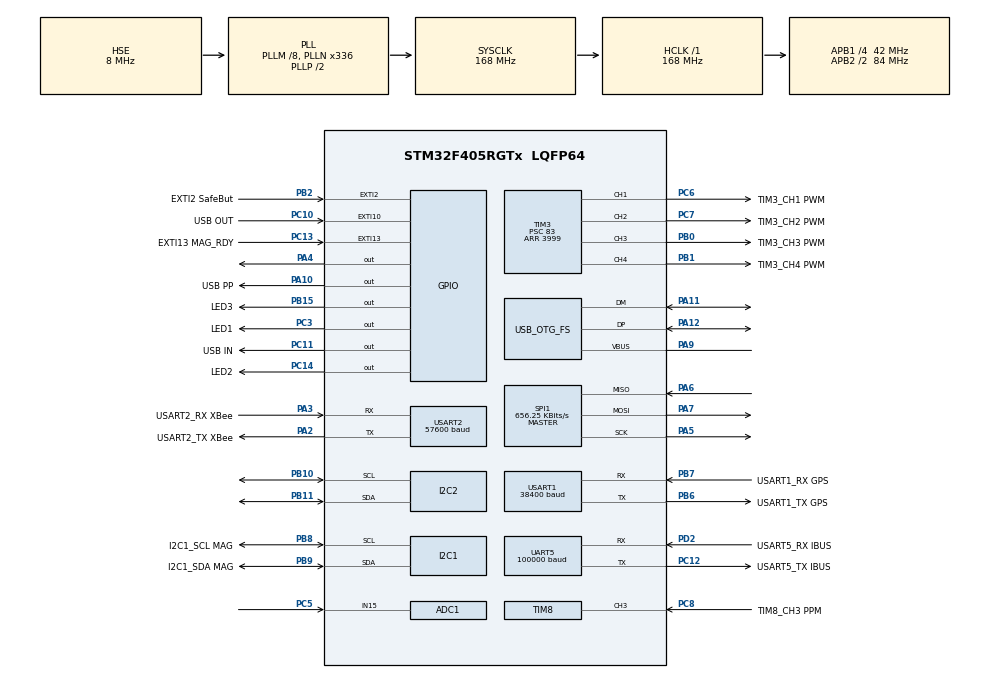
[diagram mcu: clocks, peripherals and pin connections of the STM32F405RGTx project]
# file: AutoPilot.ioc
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ADC1.Channel-16\#ChannelRegularConversion=ADC_CHANNEL_15
ADC1.ClockPrescaler=ADC_CLOCK_SYNC_PCLK_DIV4
ADC1.ContinuousConvMode=DISABLE
ADC1.DMAContinuousRequests=DISABLE
ADC1.DataAlign=ADC_DATAALIGN_RIGHT
ADC1.DiscontinuousConvMode=DISABLE
ADC1.EOCSelection=ADC_EOC_SINGLE_CONV
ADC1.EnableAnalogWatchDog=false
ADC1.ExternalTrigConvEdge=ADC_EXTERNALTRIGCONVEDGE_NONE
ADC1.InjNumberOfConversion=0
ADC1.NbrOfConversion=1
ADC1.NbrOfConversionFlag=1
ADC1.Rank-16\#ChannelRegularConversion=1
ADC1.Resolution=ADC_RESOLUTION_12B
ADC1.SamplingTime-16\#ChannelRegularConversion=ADC_SAMPLETIME_3CYCLES
ADC1.ScanConvMode=DISABLE
ADC1.master=1
Dma.I2C1_RX.5.Direction=DMA_PERIPH_TO_MEMORY
Dma.I2C1_RX.5.FIFOMode=DMA_FIFOMODE_DISABLE
Dma.I2C1_RX.5.Instance=DMA1_Stream0
Dma.I2C1_RX.5.MemDataAlignment=DMA_MDATAALIGN_BYTE
Dma.I2C1_RX.5.MemInc=DMA_MINC_ENABLE
Dma.I2C1_RX.5.Mode=DMA_NORMAL
Dma.I2C1_RX.5.PeriphDataAlignment=DMA_PDATAALIGN_BYTE
Dma.I2C1_RX.5.PeriphInc=DMA_PINC_DISABLE
Dma.I2C1_RX.5.Priority=DMA_PRIORITY_LOW
Dma.I2C2_RX.6.Direction=DMA_PERIPH_TO_MEMORY
Dma.I2C2_RX.6.FIFOMode=DMA_FIFOMODE_DISABLE
Dma.I2C2_RX.6.Instance=DMA1_Stream2
Dma.I2C2_RX.6.MemDataAlignment=DMA_MDATAALIGN_BYTE
Dma.I2C2_RX.6.MemInc=DMA_MINC_ENABLE
Dma.I2C2_RX.6.Mode=DMA_NORMAL
Dma.I2C2_RX.6.PeriphDataAlignment=DMA_PDATAALIGN_BYTE
Dma.I2C2_RX.6.PeriphInc=DMA_PINC_DISABLE
Dma.I2C2_RX.6.Priority=DMA_PRIORITY_LOW
Dma.I2C2_TX.7.Direction=DMA_MEMORY_TO_PERIPH
Dma.I2C2_TX.7.FIFOMode=DMA_FIFOMODE_DISABLE
Dma.I2C2_TX.7.Instance=DMA1_Stream7
Dma.I2C2_TX.7.MemDataAlignment=DMA_MDATAALIGN_BYTE
Dma.I2C2_TX.7.MemInc=DMA_MINC_ENABLE
Dma.I2C2_TX.7.Mode=DMA_NORMAL
Dma.I2C2_TX.7.PeriphDataAlignment=DMA_PDATAALIGN_BYTE
Dma.I2C2_TX.7.PeriphInc=DMA_PINC_DISABLE
Dma.I2C2_TX.7.Priority=DMA_PRIORITY_LOW
Dma.Request0=USART2_TX
Dma.Request1=USART2_RX
Dma.Request2=USART1_RX
Dma.Request3=SPI1_RX
Dma.Request4=SPI1_TX
Dma.Request5=I2C1_RX
Dma.Request6=I2C2_RX
Dma.Request7=I2C2_TX
Dma.SPI1_RX.3.Direction=DMA_PERIPH_TO_MEMORY
Dma.SPI1_RX.3.FIFOMode=DMA_FIFOMODE_DISABLE
Dma.SPI1_RX.3.Instance=DMA2_Stream2
Dma.SPI1_RX.3.MemDataAlignment=DMA_MDATAALIGN_BYTE
Dma.SPI1_RX.3.MemInc=DMA_MINC_ENABLE
Dma.SPI1_RX.3.Mode=DMA_NORMAL
Dma.SPI1_RX.3.PeriphDataAlignment=DMA_PDATAALIGN_BYTE
Dma.SPI1_RX.3.PeriphInc=DMA_PINC_DISABLE
Dma.SPI1_RX.3.Priority=DMA_PRIORITY_HIGH
Dma.SPI1_TX.4.Direction=DMA_MEMORY_TO_PERIPH
Dma.SPI1_TX.4.FIFOMode=DMA_FIFOMODE_DISABLE
Dma.SPI1_TX.4.Instance=DMA2_Stream3
Dma.SPI1_TX.4.MemDataAlignment=DMA_MDATAALIGN_BYTE
Dma.SPI1_TX.4.MemInc=DMA_MINC_ENABLE
Dma.SPI1_TX.4.Mode=DMA_NORMAL
Dma.SPI1_TX.4.PeriphDataAlignment=DMA_PDATAALIGN_BYTE
Dma.SPI1_TX.4.PeriphInc=DMA_PINC_DISABLE
Dma.SPI1_TX.4.Priority=DMA_PRIORITY_HIGH
Dma.USART1_RX.2.Direction=DMA_PERIPH_TO_MEMORY
Dma.USART1_RX.2.FIFOMode=DMA_FIFOMODE_DISABLE
Dma.USART1_RX.2.Instance=DMA2_Stream5
Dma.USART1_RX.2.MemDataAlignment=DMA_MDATAALIGN_BYTE
Dma.USART1_RX.2.MemInc=DMA_MINC_ENABLE
Dma.USART1_RX.2.Mode=DMA_NORMAL
Dma.USART1_RX.2.PeriphDataAlignment=DMA_PDATAALIGN_BYTE
Dma.USART1_RX.2.PeriphInc=DMA_PINC_DISABLE
Dma.USART1_RX.2.Priority=DMA_PRIORITY_LOW
Dma.USART2_RX.1.Direction=DMA_PERIPH_TO_MEMORY
Dma.USART2_RX.1.FIFOMode=DMA_FIFOMODE_DISABLE
Dma.USART2_RX.1.Instance=DMA1_Stream5
Dma.USART2_RX.1.MemDataAlignment=DMA_MDATAALIGN_BYTE
Dma.USART2_RX.1.MemInc=DMA_MINC_ENABLE
Dma.USART2_RX.1.Mode=DMA_NORMAL
Dma.USART2_RX.1.PeriphDataAlignment=DMA_PDATAALIGN_BYTE
Dma.USART2_RX.1.PeriphInc=DMA_PINC_DISABLE
Dma.USART2_RX.1.Priority=DMA_PRIORITY_LOW
Dma.USART2_TX.0.Direction=DMA_MEMORY_TO_PERIPH
Dma.USART2_TX.0.FIFOMode=DMA_FIFOMODE_DISABLE
Dma.USART2_TX.0.Instance=DMA1_Stream6
Dma.USART2_TX.0.MemDataAlignment=DMA_MDATAALIGN_BYTE
Dma.USART2_TX.0.MemInc=DMA_MINC_ENABLE
Dma.USART2_TX.0.Mode=DMA_NORMAL
Dma.USART2_TX.0.PeriphDataAlignment=DMA_PDATAALIGN_BYTE
Dma.USART2_TX.0.PeriphInc=DMA_PINC_DISABLE
Dma.USART2_TX.0.Priority=DMA_PRIORITY_LOW
FREERTOS.INCLUDE_vTaskDelayUntil=1
FREERTOS.Tasks01=defaultTask,0,128,StartDefaultTask,Default
I2C1.I2C_Mode=I2C_Fast
I2C2.I2C_Mode=I2C_Fast
I2C2.OwnAddress=0x50
Mcu.Family=STM32F4
Mcu.Name=STM32F405RGTx
Mcu.Package=LQFP64
NVIC.DMA1_Stream0_IRQn=true\:0\:0\:false\:false\:true\:false
NVIC.DMA1_Stream2_IRQn=true\:5\:0\:false\:false\:true\:true
NVIC.DMA1_Stream5_IRQn=true\:0\:0\:false\:false\:true\:false
NVIC.DMA1_Stream6_IRQn=true\:5\:0\:false\:false\:true\:true
NVIC.DMA1_Stream7_IRQn=true\:5\:0\:false\:false\:true\:true
NVIC.DMA2_Stream2_IRQn=true\:5\:0\:false\:false\:true\:true
NVIC.DMA2_Stream3_IRQn=true\:5\:0\:false\:false\:true\:true
NVIC.DMA2_Stream5_IRQn=true\:5\:0\:false\:false\:true\:true
NVIC.EXTI15_10_IRQn=true\:15\:0\:true\:false\:true\:true
NVIC.EXTI2_IRQn=true\:9\:0\:true\:false\:true\:true
NVIC.FLASH_IRQn=true\:7\:0\:true\:false\:true\:true
NVIC.I2C1_EV_IRQn=true\:5\:0\:true\:false\:true\:true
NVIC.I2C2_EV_IRQn=true\:5\:0\:false\:false\:true\:true
NVIC.OTG_FS_IRQn=true\:5\:0\:false\:false\:true\:true
NVIC.PriorityGroup=NVIC_PRIORITYGROUP_4
NVIC.SPI1_IRQn=true\:6\:0\:true\:false\:true\:true
NVIC.TIM1_UP_TIM10_IRQn=true\:0\:0\:false\:false\:true\:false
NVIC.TIM4_IRQn=true\:0\:0\:false\:false\:true\:false
NVIC.TIM8_CC_IRQn=true\:13\:0\:true\:false\:true\:true
NVIC.TimeBase=TIM1_UP_TIM10_IRQn
NVIC.TimeBaseIP=TIM1
NVIC.UART5_IRQn=true\:12\:0\:true\:false\:true\:true
NVIC.USART1_IRQn=true\:11\:0\:true\:false\:true\:true
NVIC.USART2_IRQn=true\:10\:0\:true\:false\:true\:true
PA10.GPIO_Label=USB PP
PA10.Signal=GPIO_Output
PA11.Mode=Device_Only
PA11.Signal=USB_OTG_FS_DM
PA12.Mode=Device_Only
PA12.Signal=USB_OTG_FS_DP
PA13.Mode=JTAG_5_pins
PA13.Signal=SYS_JTMS-SWDIO
PA14.Mode=JTAG_5_pins
PA14.Signal=SYS_JTCK-SWCLK
PA15.Mode=JTAG_5_pins
PA15.Signal=SYS_JTDI
PA2.GPIO_Label=USART2_TX XBee
PA2.Mode=Asynchronous
PA2.Signal=USART2_TX
PA3.GPIO_Label=USART2_RX XBee
PA3.Mode=Asynchronous
PA3.Signal=USART2_RX
PA4.GPIO_Speed=GPIO_SPEED_FREQ_VERY_HIGH
PA4.PinState=GPIO_PIN_SET
PA4.Signal=GPIO_Output
PA5.Mode=Full_Duplex_Master
PA5.Signal=SPI1_SCK
PA6.Mode=Full_Duplex_Master
PA6.Signal=SPI1_MISO
PA7.Mode=Full_Duplex_Master
PA7.Signal=SPI1_MOSI
PA9.Mode=Activate_VBUS
PA9.Signal=USB_OTG_FS_VBUS
PB0.GPIO_Label=TIM3_CH3 PWM
PB0.Signal=S_TIM3_CH3
PB1.GPIO_Label=TIM3_CH4 PWM
PB1.Signal=S_TIM3_CH4
PB10.Mode=I2C
PB10.Signal=I2C2_SCL
PB11.Mode=I2C
PB11.Signal=I2C2_SDA
PB15.GPIO_Label=LED3
PB15.Signal=GPIO_Output
PB2.GPIO_Label=EXTI2 SafeBut
PB2.GPIO_ModeDefaultEXTI=GPIO_MODE_IT_RISING_FALLING
PB2.Signal=GPXTI2
PB3.Mode=JTAG_5_pins
PB3.Signal=SYS_JTDO-SWO
PB4.Mode=JTAG_5_pins
PB4.Signal=SYS_JTRST
PB6.GPIO_Label=USART1_TX GPS
PB6.Mode=Asynchronous
PB6.Signal=USART1_TX
PB7.GPIO_Label=USART1_RX GPS
PB7.Mode=Asynchronous
PB7.Signal=USART1_RX
PB8.GPIO_Label=I2C1_SCL MAG
PB8.Mode=I2C
PB8.Signal=I2C1_SCL
PB9.GPIO_Label=I2C1_SDA MAG
PB9.Mode=I2C
PB9.Signal=I2C1_SDA
PC10.GPIO_Label=USB OUT
PC10.GPIO_ModeDefaultEXTI=GPIO_MODE_IT_RISING_FALLING
PC10.Signal=GPXTI10
PC11.GPIO_Label=USB IN
PC11.Signal=GPIO_Output
PC12.GPIO_Label=USART5_TX IBUS
PC12.Mode=Asynchronous
PC12.Signal=UART5_TX
PC13-ANTI_TAMP.GPIO_Label=EXTI13 MAG_RDY
PC13-ANTI_TAMP.Signal=GPXTI13
PC14-OSC32_IN.GPIO_Label=LED2
PC14-OSC32_IN.Signal=GPIO_Output
PC3.GPIO_Label=LED1
PC3.Signal=GPIO_Output
PC5.Signal=ADCx_IN15
PC6.GPIO_Label=TIM3_CH1 PWM
PC6.Signal=S_TIM3_CH1
PC7.GPIO_Label=TIM3_CH2 PWM
PC7.Signal=S_TIM3_CH2
PC8.GPIO_Label=TIM8_CH3 PPM
PC8.Signal=S_TIM8_CH3
PD2.GPIO_Label=USART5_RX IBUS
PD2.Mode=Asynchronous
PD2.Signal=UART5_RX
PH0-OSC_IN.Mode=HSE-External-Oscillator
PH0-OSC_IN.Signal=RCC_OSC_IN
PH1-OSC_OUT.Mode=HSE-External-Oscillator
PH1-OSC_OUT.Signal=RCC_OSC_OUT
ProjectManager.HeapSize=0x200
ProjectManager.StackSize=0x400
ProjectManager.TargetToolchain=MDK-ARM V5
RCC.48MHZClocksFreq_Value=48000000
RCC.AHBFreq_Value=168000000
RCC.APB1CLKDivider=RCC_HCLK_DIV4
RCC.APB1Freq_Value=42000000
RCC.APB1TimFreq_Value=84000000
RCC.APB2CLKDivider=RCC_HCLK_DIV2
RCC.APB2Freq_Value=84000000
RCC.APB2TimFreq_Value=168000000
RCC.CortexFreq_Value=168000000
RCC.HCLKFreq_Value=168000000
RCC.HSE_VALUE=8000000
RCC.HSI_VALUE=16000000
RCC.LSE_VALUE=32768
RCC.PLLM=8
RCC.PLLN=336
RCC.PLLQ=7
RCC.SYSCLKFreq_VALUE=168000000
RCC.SYSCLKSource=RCC_SYSCLKSOURCE_PLLCLK
RCC.VCOOutputFreq_Value=336000000
SH.ADCx_IN15.0=ADC1_IN15,IN15
SH.S_TIM3_CH1.0=TIM3_CH1,PWM Generation1 CH1
SH.S_TIM3_CH2.0=TIM3_CH2,PWM Generation2 CH2
SH.S_TIM3_CH3.0=TIM3_CH3,PWM Generation3 CH3
SH.S_TIM3_CH4.0=TIM3_CH4,PWM Generation4 CH4
SH.S_TIM8_CH3.0=TIM8_CH3,Input_Capture3_from_TI3
SPI1.BaudRatePrescaler=SPI_BAUDRATEPRESCALER_128
SPI1.CLKPhase=SPI_PHASE_1EDGE
SPI1.CLKPolarity=SPI_POLARITY_LOW
SPI1.CalculateBaudRate=656.25 KBits/s
SPI1.Direction=SPI_DIRECTION_2LINES
SPI1.FirstBit=SPI_FIRSTBIT_MSB
SPI1.Mode=SPI_MODE_MASTER
SPI1.VirtualType=VM_MASTER
TIM3.Channel-PWM\ Generation1\ CH1=TIM_CHANNEL_1
TIM3.Channel-PWM\ Generation2\ CH2=TIM_CHANNEL_2
TIM3.Channel-PWM\ Generation3\ CH3=TIM_CHANNEL_3
TIM3.Channel-PWM\ Generation4\ CH4=TIM_CHANNEL_4
TIM3.Period=3999
TIM3.Prescaler=83
TIM4.Period=7999
TIM4.Prescaler=20
TIM8.Channel-Input_Capture3_from_TI3=TIM_CHANNEL_3
TIM8.ICPolarity_CH3=TIM_INPUTCHANNELPOLARITY_BOTHEDGE
TIM8.Period=39999
TIM8.Prescaler=83
UART5.BaudRate=100000
UART5.Mode=UART_MODE_RX
UART5.Parity=UART_PARITY_EVEN
UART5.StopBits=UART_STOPBITS_2
UART5.VirtualMode=Asynchronous
UART5.WordLength=UART_WORDLENGTH_9B
USART1.BaudRate=38400
USART1.VirtualMode=VM_ASYNC
USART2.BaudRate=57600
USART2.VirtualMode=VM_ASYNC
USB_DEVICE.CLASS_NAME_FS=CDC
USB_DEVICE.USBD_HandleTypeDef-CDC_FS=hUsbDeviceFS
USB_DEVICE.VirtualMode-CDC_FS=Cdc
USB_DEVICE.VirtualModeFS=Cdc_FS
USB_OTG_FS.VirtualMode=Device_Only
VP_CRC_VS_CRC.Mode=CRC_Activate
VP_FREERTOS_VS_ENABLE.Mode=Enabled
VP_SYS_VS_tim1.Mode=TIM1
VP_TIM4_VS_ClockSourceINT.Mode=Internal
VP_TIM8_VS_ClockSourceINT.Mode=Internal
VP_USB_DEVICE_VS_USB_DEVICE_CDC_FS.Mode=CDC_FS
board=AutoPilot

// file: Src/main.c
/**
  ******************************************************************************
  * File Name          : main.c
  * Description        : Main program body
  ******************************************************************************
  *
  * COPYRIGHT(c) 2016 STMicroelectronics
  *
  * Redistribution and use in source and binary forms, with or without modification,
  * are permitted provided that the following conditions are met:
  *   1. Redistributions of source code must retain the above copyright notice,
  *      this list of conditions and the following disclaimer.
  *   2. Redistributions in binary form must reproduce the above copyright notice,
  *      this list of conditions and the following disclaimer in the documentation
  *      and/or other materials provided with the distribution.
  *   3. Neither the name of STMicroelectronics nor the names of its contributors
  *      may be used to endorse or promote products derived from this software
  *      without specific prior written permission.
  *
  * THIS SOFTWARE IS PROVIDED BY THE COPYRIGHT HOLDERS AND CONTRIBUTORS "AS IS"
  * AND ANY EXPRESS OR IMPLIED WARRANTIES, INCLUDING, BUT NOT LIMITED TO, THE
  * IMPLIED WARRANTIES OF MERCHANTABILITY AND FITNESS FOR A PARTICULAR PURPOSE ARE
  * DISCLAIMED. IN NO EVENT SHALL THE COPYRIGHT HOLDER OR CONTRIBUTORS BE LIABLE
  * FOR ANY DIRECT, INDIRECT, INCIDENTAL, SPECIAL, EXEMPLARY, OR CONSEQUENTIAL
  * DAMAGES (INCLUDING, BUT NOT LIMITED TO, PROCUREMENT OF SUBSTITUTE GOODS OR
  * SERVICES; LOSS OF USE, DATA, OR PROFITS; OR BUSINESS INTERRUPTION) HOWEVER
  * CAUSED AND ON ANY THEORY OF LIABILITY, WHETHER IN CONTRACT, STRICT LIABILITY,
  * OR TORT (INCLUDING NEGLIGENCE OR OTHERWISE) ARISING IN ANY WAY OUT OF THE USE
  * OF THIS SOFTWARE, EVEN IF ADVISED OF THE POSSIBILITY OF SUCH DAMAGE.
  *
  ******************************************************************************
  */
#include "stm32f4xx_hal.h"
#include "cmsis_os.h"
#include "usb_device.h"

/* USER CODE BEGIN Includes */
#include "../Modules/task_manager.h"

/*
#include "../Devices/data_link.h"
#include "../Devices/motor_pwm.h"
#include "../Devices/GPS.h"
#include "../Devices/battery.h"
#include "../Devices/led.h"
#include "../Devices/receiver.h"
#include "../Devices/mpu6000_spi.h"
#include "../Devices/rom.h"
#include "../Devices/hmc5883l_i2c.h"
#include "../Modules/sensors_task.h"
#include "../Modules/commander.h"
#include "../Modules/stabilizer.h"
*/

/* USER CODE END Includes */

ADC_HandleTypeDef hadc1;

CRC_HandleTypeDef hcrc;

I2C_HandleTypeDef hi2c1;
I2C_HandleTypeDef hi2c2;
DMA_HandleTypeDef hdma_i2c1_rx;
DMA_HandleTypeDef hdma_i2c2_rx;
DMA_HandleTypeDef hdma_i2c2_tx;

SPI_HandleTypeDef hspi1;
DMA_HandleTypeDef hdma_spi1_rx;
DMA_HandleTypeDef hdma_spi1_tx;

TIM_HandleTypeDef htim3;
TIM_HandleTypeDef htim4;
TIM_HandleTypeDef htim8;

UART_HandleTypeDef huart5;
UART_HandleTypeDef huart1;
UART_HandleTypeDef huart2;
DMA_HandleTypeDef hdma_usart1_rx;
DMA_HandleTypeDef hdma_usart2_tx;
DMA_HandleTypeDef hdma_usart2_rx;

osThreadId defaultTaskHandle;

/* USER CODE BEGIN PV */
/* Private variables ---------------------------------------------------------*/

/* USER CODE END PV */

void SystemClock_Config(void);
void Error_Handler(void);
static void MX_GPIO_Init(void);
static void MX_DMA_Init(void);
static void MX_ADC1_Init(void);
static void MX_CRC_Init(void);
static void MX_I2C1_Init(void);
static void MX_UART5_Init(void);
static void MX_TIM3_Init(void);
static void MX_USART1_UART_Init(void);
static void MX_I2C2_Init(void);
static void MX_TIM8_Init(void);
static void MX_SPI1_Init(void);
static void MX_USART2_UART_Init(void);
static void MX_TIM4_Init(void);
void StartDefaultTask(void const * argument);

void HAL_TIM_MspPostInit(TIM_HandleTypeDef *htim);

/* USER CODE BEGIN PFP */
/* Private function prototypes -----------------------------------------------*/

/* USER CODE END PFP */

int main(void)
{

  /* MCU Configuration----------------------------------------------------------*/

  /* Reset of all peripherals, Initializes the Flash interface and the Systick. */
  HAL_Init();

  /* Configure the system clock */
  SystemClock_Config();

  /* Initialize all configured peripherals */
  MX_GPIO_Init();
  MX_DMA_Init();
  MX_ADC1_Init();
  MX_CRC_Init();
  MX_I2C1_Init();
  MX_UART5_Init();
  MX_TIM3_Init();
  MX_USART1_UART_Init();
  MX_I2C2_Init();
  MX_TIM8_Init();
  MX_SPI1_Init();
  MX_USART2_UART_Init();
  MX_TIM4_Init();

  /* Create the thread(s) */
  /* definition and creation of defaultTask */
  osThreadDef(defaultTask, StartDefaultTask, osPriorityNormal, 0, 128);
  defaultTaskHandle = osThreadCreate(osThread(defaultTask), NULL);

  /* USER CODE BEGIN RTOS_THREADS */
  /* add threads, ... */
//	xTaskCreate( vLED1Task, "LED0", configMINIMAL_STACK_SIZE, NULL, tskIDLE_PRIORITY+3, NULL );
//  xTaskCreate( vLED2Task, "LED1", configMINIMAL_STACK_SIZE, NULL, tskIDLE_PRIORITY+3, NULL );
//  GPSInit();
/*	led_init();
	motor_init();
	data_link_init();
	receiver_init();
//	data_send_start();
	eeprom_init();
	battery_init();
	mpu6000_cfg();
	hmc5883l_cfg();
	mpu_fast_init();
	hmc_fast_init();
	sensorsTaskInit();
	commanderInit();*/
//	stabilizerInit();
	taskManagerInit();

	vTaskStartScheduler();
//	start_manager();
  /* USER CODE END RTOS_THREADS */

  /* Start scheduler */
  osKernelStart();

  /* We should never get here as control is now taken by the scheduler */

  /* Infinite loop */
  while (1)
  {

  }

}

/** System Clock Configuration
*/
void SystemClock_Config(void)
{

  RCC_OscInitTypeDef RCC_OscInitStruct;
  RCC_ClkInitTypeDef RCC_ClkInitStruct;

  __HAL_RCC_PWR_CLK_ENABLE();

  __HAL_PWR_VOLTAGESCALING_CONFIG(PWR_REGULATOR_VOLTAGE_SCALE1);

  RCC_OscInitStruct.OscillatorType = RCC_OSCILLATORTYPE_HSE;
  RCC_OscInitStruct.HSEState = RCC_HSE_ON;
  RCC_OscInitStruct.PLL.PLLState = RCC_PLL_ON;
  RCC_OscInitStruct.PLL.PLLSource = RCC_PLLSOURCE_HSE;
  RCC_OscInitStruct.PLL.PLLM = 8;
  RCC_OscInitStruct.PLL.PLLN = 336;
  RCC_OscInitStruct.PLL.PLLP = RCC_PLLP_DIV2;
  RCC_OscInitStruct.PLL.PLLQ = 7;
  if (HAL_RCC_OscConfig(&RCC_OscInitStruct) != HAL_OK)
  {
    Error_Handler();
  }

  RCC_ClkInitStruct.ClockType = RCC_CLOCKTYPE_HCLK|RCC_CLOCKTYPE_SYSCLK
                              |RCC_CLOCKTYPE_PCLK1|RCC_CLOCKTYPE_PCLK2;
  RCC_ClkInitStruct.SYSCLKSource = RCC_SYSCLKSOURCE_PLLCLK;
  RCC_ClkInitStruct.AHBCLKDivider = RCC_SYSCLK_DIV1;
  RCC_ClkInitStruct.APB1CLKDivider = RCC_HCLK_DIV4;
  RCC_ClkInitStruct.APB2CLKDivider = RCC_HCLK_DIV2;
  if (HAL_RCC_ClockConfig(&RCC_ClkInitStruct, FLASH_LATENCY_5) != HAL_OK)
  {
    Error_Handler();
  }

  HAL_SYSTICK_Config(HAL_RCC_GetHCLKFreq()/1000);

  HAL_SYSTICK_CLKSourceConfig(SYSTICK_CLKSOURCE_HCLK);

  /* SysTick_IRQn interrupt configuration */
  HAL_NVIC_SetPriority(SysTick_IRQn, 15, 0);
}

/* ADC1 init function */
static void MX_ADC1_Init(void)
{

  ADC_ChannelConfTypeDef sConfig;

    /**Configure the global features of the ADC (Clock, Resolution, Data Alignment and number of conversion)
    */
  hadc1.Instance = ADC1;
  hadc1.Init.ClockPrescaler = ADC_CLOCK_SYNC_PCLK_DIV4;
  hadc1.Init.Resolution = ADC_RESOLUTION_12B;
  hadc1.Init.ScanConvMode = DISABLE;
  hadc1.Init.ContinuousConvMode = DISABLE;
  hadc1.Init.DiscontinuousConvMode = DISABLE;
  hadc1.Init.ExternalTrigConvEdge = ADC_EXTERNALTRIGCONVEDGE_NONE;
  hadc1.Init.DataAlign = ADC_DATAALIGN_RIGHT;
  hadc1.Init.NbrOfConversion = 1;
  hadc1.Init.DMAContinuousRequests = DISABLE;
  hadc1.Init.EOCSelection = ADC_EOC_SINGLE_CONV;
  if (HAL_ADC_Init(&hadc1) != HAL_OK)
  {
    Error_Handler();
  }

    /**Configure for the selected ADC regular channel its corresponding rank in the sequencer and its sample time.
    */
  sConfig.Channel = ADC_CHANNEL_15;
  sConfig.Rank = 1;
  sConfig.SamplingTime = ADC_SAMPLETIME_3CYCLES;
  if (HAL_ADC_ConfigChannel(&hadc1, &sConfig) != HAL_OK)
  {
    Error_Handler();
  }

}

/* CRC init function */
static void MX_CRC_Init(void)
{

  hcrc.Instance = CRC;
  if (HAL_CRC_Init(&hcrc) != HAL_OK)
  {
    Error_Handler();
  }

}

/* I2C1 init function */
static void MX_I2C1_Init(void)
{

  hi2c1.Instance = I2C1;
  hi2c1.Init.ClockSpeed = 400000;
  hi2c1.Init.DutyCycle = I2C_DUTYCYCLE_2;
  hi2c1.Init.OwnAddress1 = 0;
  hi2c1.Init.AddressingMode = I2C_ADDRESSINGMODE_7BIT;
  hi2c1.Init.DualAddressMode = I2C_DUALADDRESS_DISABLE;
  hi2c1.Init.OwnAddress2 = 0;
  hi2c1.Init.GeneralCallMode = I2C_GENERALCALL_DISABLE;
  hi2c1.Init.NoStretchMode = I2C_NOSTRETCH_DISABLE;
  if (HAL_I2C_Init(&hi2c1) != HAL_OK)
  {
    Error_Handler();
  }

}

/* I2C2 init function */
static void MX_I2C2_Init(void)
{

  hi2c2.Instance = I2C2;
  hi2c2.Init.ClockSpeed = 400000;
  hi2c2.Init.DutyCycle = I2C_DUTYCYCLE_2;
  hi2c2.Init.OwnAddress1 = 160;
  hi2c2.Init.AddressingMode = I2C_ADDRESSINGMODE_7BIT;
  hi2c2.Init.DualAddressMode = I2C_DUALADDRESS_DISABLE;
  hi2c2.Init.OwnAddress2 = 0;
  hi2c2.Init.GeneralCallMode = I2C_GENERALCALL_DISABLE;
  hi2c2.Init.NoStretchMode = I2C_NOSTRETCH_DISABLE;
  if (HAL_I2C_Init(&hi2c2) != HAL_OK)
  {
    Error_Handler();
  }

}

/* SPI1 init function */
static void MX_SPI1_Init(void)
{

  hspi1.Instance = SPI1;
  hspi1.Init.Mode = SPI_MODE_MASTER;
  hspi1.Init.Direction = SPI_DIRECTION_2LINES;
  hspi1.Init.DataSize = SPI_DATASIZE_8BIT;
  hspi1.Init.CLKPolarity = SPI_POLARITY_LOW;
  hspi1.Init.CLKPhase = SPI_PHASE_1EDGE;
  hspi1.Init.NSS = SPI_NSS_SOFT;
  hspi1.Init.BaudRatePrescaler = SPI_BAUDRATEPRESCALER_128;
  hspi1.Init.FirstBit = SPI_FIRSTBIT_MSB;
  hspi1.Init.TIMode = SPI_TIMODE_DISABLE;
  hspi1.Init.CRCCalculation = SPI_CRCCALCULATION_DISABLE;
  hspi1.Init.CRCPolynomial = 10;
  if (HAL_SPI_Init(&hspi1) != HAL_OK)
  {
    Error_Handler();
  }

}

/* TIM3 init function */
static void MX_TIM3_Init(void)
{

  TIM_MasterConfigTypeDef sMasterConfig;
  TIM_OC_InitTypeDef sConfigOC;

  htim3.Instance = TIM3;
  htim3.Init.Prescaler = 83;
  htim3.Init.CounterMode = TIM_COUNTERMODE_UP;
  htim3.Init.Period = 3999;
  htim3.Init.ClockDivision = TIM_CLOCKDIVISION_DIV1;
  if (HAL_TIM_PWM_Init(&htim3) != HAL_OK)
  {
    Error_Handler();
  }

  sMasterConfig.MasterOutputTrigger = TIM_TRGO_RESET;
  sMasterConfig.MasterSlaveMode = TIM_MASTERSLAVEMODE_DISABLE;
  if (HAL_TIMEx_MasterConfigSynchronization(&htim3, &sMasterConfig) != HAL_OK)
  {
    Error_Handler();
  }

  sConfigOC.OCMode = TIM_OCMODE_PWM1;
  sConfigOC.Pulse = 0;
  sConfigOC.OCPolarity = TIM_OCPOLARITY_HIGH;
  sConfigOC.OCFastMode = TIM_OCFAST_DISABLE;
  if (HAL_TIM_PWM_ConfigChannel(&htim3, &sConfigOC, TIM_CHANNEL_1) != HAL_OK)
  {
    Error_Handler();
  }

  if (HAL_TIM_PWM_ConfigChannel(&htim3, &sConfigOC, TIM_CHANNEL_2) != HAL_OK)
  {
    Error_Handler();
  }

  if (HAL_TIM_PWM_ConfigChannel(&htim3, &sConfigOC, TIM_CHANNEL_3) != HAL_OK)
  {
    Error_Handler();
  }

  if (HAL_TIM_PWM_ConfigChannel(&htim3, &sConfigOC, TIM_CHANNEL_4) != HAL_OK)
  {
    Error_Handler();
  }

  HAL_TIM_MspPostInit(&htim3);

}

/* TIM4 init function */
static void MX_TIM4_Init(void)
{

  TIM_ClockConfigTypeDef sClockSourceConfig;
  TIM_MasterConfigTypeDef sMasterConfig;

  htim4.Instance = TIM4;
  htim4.Init.Prescaler = 20;
  htim4.Init.CounterMode = TIM_COUNTERMODE_UP;
  htim4.Init.Period = 7999;
  htim4.Init.ClockDivision = TIM_CLOCKDIVISION_DIV1;
  if (HAL_TIM_Base_Init(&htim4) != HAL_OK)
  {
    Error_Handler();
  }

  sClockSourceConfig.ClockSource = TIM_CLOCKSOURCE_INTERNAL;
  if (HAL_TIM_ConfigClockSource(&htim4, &sClockSourceConfig) != HAL_OK)
  {
    Error_Handler();
  }

  sMasterConfig.MasterOutputTrigger = TIM_TRGO_RESET;
  sMasterConfig.MasterSlaveMode = TIM_MASTERSLAVEMODE_DISABLE;
  if (HAL_TIMEx_MasterConfigSynchronization(&htim4, &sMasterConfig) != HAL_OK)
  {
    Error_Handler();
  }

}

/* TIM8 init function */
static void MX_TIM8_Init(void)
{

  TIM_ClockConfigTypeDef sClockSourceConfig;
  TIM_MasterConfigTypeDef sMasterConfig;
  TIM_IC_InitTypeDef sConfigIC;

  htim8.Instance = TIM8;
  htim8.Init.Prescaler = 83;
  htim8.Init.CounterMode = TIM_COUNTERMODE_UP;
  htim8.Init.Period = 39999;
  htim8.Init.ClockDivision = TIM_CLOCKDIVISION_DIV1;
  htim8.Init.RepetitionCounter = 0;
  if (HAL_TIM_Base_Init(&htim8) != HAL_OK)
  {
    Error_Handler();
  }

  sClockSourceConfig.ClockSource = TIM_CLOCKSOURCE_INTERNAL;
  if (HAL_TIM_ConfigClockSource(&htim8, &sClockSourceConfig) != HAL_OK)
  {
    Error_Handler();
  }

  if (HAL_TIM_IC_Init(&htim8) != HAL_OK)
  {
    Error_Handler();
  }

  sMasterConfig.MasterOutputTrigger = TIM_TRGO_RESET;
  sMasterConfig.MasterSlaveMode = TIM_MASTERSLAVEMODE_DISABLE;
  if (HAL_TIMEx_MasterConfigSynchronization(&htim8, &sMasterConfig) != HAL_OK)
  {
    Error_Handler();
  }

  sConfigIC.ICPolarity = TIM_INPUTCHANNELPOLARITY_BOTHEDGE;
  sConfigIC.ICSelection = TIM_ICSELECTION_DIRECTTI;
  sConfigIC.ICPrescaler = TIM_ICPSC_DIV1;
  sConfigIC.ICFilter = 0;
  if (HAL_TIM_IC_ConfigChannel(&htim8, &sConfigIC, TIM_CHANNEL_3) != HAL_OK)
  {
    Error_Handler();
  }

}

/* UART5 init function */
static void MX_UART5_Init(void)
{

  huart5.Instance = UART5;
  huart5.Init.BaudRate = 100000;
  huart5.Init.WordLength = UART_WORDLENGTH_9B;
  huart5.Init.StopBits = UART_STOPBITS_2;
  huart5.Init.Parity = UART_PARITY_EVEN;
  huart5.Init.Mode = UART_MODE_RX;
  huart5.Init.HwFlowCtl = UART_HWCONTROL_NONE;
  huart5.Init.OverSampling = UART_OVERSAMPLING_16;
  if (HAL_UART_Init(&huart5) != HAL_OK)
  {
    Error_Handler();
  }

}

/* USART1 init function */
static void MX_USART1_UART_Init(void)
{

  huart1.Instance = USART1;
  huart1.Init.BaudRate = 9600;
  huart1.Init.WordLength = UART_WORDLENGTH_8B;
  huart1.Init.StopBits = UART_STOPBITS_1;
  huart1.Init.Parity = UART_PARITY_NONE;
  huart1.Init.Mode = UART_MODE_TX_RX;
  huart1.Init.HwFlowCtl = UART_HWCONTROL_NONE;
  huart1.Init.OverSampling = UART_OVERSAMPLING_16;
  if (HAL_UART_Init(&huart1) != HAL_OK)
  {
    Error_Handler();
  }

}

/* USART2 init function */
static void MX_USART2_UART_Init(void)
{

  huart2.Instance = USART2;
  huart2.Init.BaudRate = 57600;
  huart2.Init.WordLength = UART_WORDLENGTH_8B;
  huart2.Init.StopBits = UART_STOPBITS_1;
  huart2.Init.Parity = UART_PARITY_NONE;
  huart2.Init.Mode = UART_MODE_TX_RX;
  huart2.Init.HwFlowCtl = UART_HWCONTROL_NONE;
  huart2.Init.OverSampling = UART_OVERSAMPLING_16;
  if (HAL_UART_Init(&huart2) != HAL_OK)
  {
    Error_Handler();
  }

}

static void MX_DMA_Init(void)
{
  /* DMA controller clock enable */
  __HAL_RCC_DMA1_CLK_ENABLE();
  __HAL_RCC_DMA2_CLK_ENABLE();

  /* DMA interrupt init */
  /* DMA1_Stream0_IRQn interrupt configuration */
  HAL_NVIC_SetPriority(DMA1_Stream0_IRQn, 0, 0);
  HAL_NVIC_EnableIRQ(DMA1_Stream0_IRQn);
  /* DMA1_Stream2_IRQn interrupt configuration */
  HAL_NVIC_SetPriority(DMA1_Stream2_IRQn, 5, 0);
  HAL_NVIC_EnableIRQ(DMA1_Stream2_IRQn);
  /* DMA1_Stream5_IRQn interrupt configuration */
  HAL_NVIC_SetPriority(DMA1_Stream5_IRQn, 0, 0);
  HAL_NVIC_EnableIRQ(DMA1_Stream5_IRQn);
  /* DMA1_Stream6_IRQn interrupt configuration */
  HAL_NVIC_SetPriority(DMA1_Stream6_IRQn, 5, 0);
  HAL_NVIC_EnableIRQ(DMA1_Stream6_IRQn);
  /* DMA1_Stream7_IRQn interrupt configuration */
  HAL_NVIC_SetPriority(DMA1_Stream7_IRQn, 5, 0);
  HAL_NVIC_EnableIRQ(DMA1_Stream7_IRQn);
  /* DMA2_Stream2_IRQn interrupt configuration */
  HAL_NVIC_SetPriority(DMA2_Stream2_IRQn, 5, 0);
  HAL_NVIC_EnableIRQ(DMA2_Stream2_IRQn);
  /* DMA2_Stream3_IRQn interrupt configuration */
  HAL_NVIC_SetPriority(DMA2_Stream3_IRQn, 5, 0);
  HAL_NVIC_EnableIRQ(DMA2_Stream3_IRQn);
  /* DMA2_Stream5_IRQn interrupt configuration */
  HAL_NVIC_SetPriority(DMA2_Stream5_IRQn, 5, 0);
  HAL_NVIC_EnableIRQ(DMA2_Stream5_IRQn);

}

/** Configure pins as
        * Analog
        * Input
        * Output
        * EVENT_OUT
        * EXTI
*/
static void MX_GPIO_Init(void)
{

  GPIO_InitTypeDef GPIO_InitStruct;

  /* GPIO Ports Clock Enable */
  __HAL_RCC_GPIOC_CLK_ENABLE();
  __HAL_RCC_GPIOH_CLK_ENABLE();
  __HAL_RCC_GPIOA_CLK_ENABLE();
  __HAL_RCC_GPIOB_CLK_ENABLE();
  __HAL_RCC_GPIOD_CLK_ENABLE();

  /*Configure GPIO pin : EXTI13_MAG_RDY_Pin */
  GPIO_InitStruct.Pin = EXTI13_MAG_RDY_Pin;
  GPIO_InitStruct.Mode = GPIO_MODE_IT_RISING;
  GPIO_InitStruct.Pull = GPIO_NOPULL;
  HAL_GPIO_Init(EXTI13_MAG_RDY_GPIO_Port, &GPIO_InitStruct);

  /*Configure GPIO pins : LED2_Pin LED1_Pin USB_IN_Pin */
  GPIO_InitStruct.Pin = LED2_Pin|LED1_Pin|USB_IN_Pin;
  GPIO_InitStruct.Mode = GPIO_MODE_OUTPUT_PP;
  GPIO_InitStruct.Pull = GPIO_NOPULL;
  GPIO_InitStruct.Speed = GPIO_SPEED_FREQ_LOW;
  HAL_GPIO_Init(GPIOC, &GPIO_InitStruct);

  /*Configure GPIO pin : PA4 */
  GPIO_InitStruct.Pin = GPIO_PIN_4;
  GPIO_InitStruct.Mode = GPIO_MODE_OUTPUT_PP;
  GPIO_InitStruct.Pull = GPIO_NOPULL;
  GPIO_InitStruct.Speed = GPIO_SPEED_FREQ_VERY_HIGH;
  HAL_GPIO_Init(GPIOA, &GPIO_InitStruct);

  /*Configure GPIO pin : EXTI2_SafeBut_Pin */
  GPIO_InitStruct.Pin = EXTI2_SafeBut_Pin;
  GPIO_InitStruct.Mode = GPIO_MODE_IT_RISING_FALLING;
  GPIO_InitStruct.Pull = GPIO_NOPULL;
  HAL_GPIO_Init(EXTI2_SafeBut_GPIO_Port, &GPIO_InitStruct);

  /*Configure GPIO pin : LED3_Pin */
  GPIO_InitStruct.Pin = LED3_Pin;
  GPIO_InitStruct.Mode = GPIO_MODE_OUTPUT_PP;
  GPIO_InitStruct.Pull = GPIO_NOPULL;
  GPIO_InitStruct.Speed = GPIO_SPEED_FREQ_LOW;
  HAL_GPIO_Init(LED3_GPIO_Port, &GPIO_InitStruct);

  /*Configure GPIO pin : USB_PP_Pin */
  GPIO_InitStruct.Pin = USB_PP_Pin;
  GPIO_InitStruct.Mode = GPIO_MODE_OUTPUT_PP;
  GPIO_InitStruct.Pull = GPIO_NOPULL;
  GPIO_InitStruct.Speed = GPIO_SPEED_FREQ_LOW;
  HAL_GPIO_Init(USB_PP_GPIO_Port, &GPIO_InitStruct);

  /*Configure GPIO pin : USB_OUT_Pin */
  GPIO_InitStruct.Pin = USB_OUT_Pin;
  GPIO_InitStruct.Mode = GPIO_MODE_IT_RISING_FALLING;
  GPIO_InitStruct.Pull = GPIO_NOPULL;
  HAL_GPIO_Init(USB_OUT_GPIO_Port, &GPIO_InitStruct);

  /*Configure GPIO pin Output Level */
  HAL_GPIO_WritePin(GPIOC, LED2_Pin|LED1_Pin|USB_IN_Pin, GPIO_PIN_RESET);

  /*Configure GPIO pin Output Level */
  HAL_GPIO_WritePin(GPIOA, GPIO_PIN_4, GPIO_PIN_SET);

  /*Configure GPIO pin Output Level */
  HAL_GPIO_WritePin(LED3_GPIO_Port, LED3_Pin, GPIO_PIN_RESET);

  /*Configure GPIO pin Output Level */
  HAL_GPIO_WritePin(USB_PP_GPIO_Port, USB_PP_Pin, GPIO_PIN_RESET);

  /* EXTI interrupt init*/
  HAL_NVIC_SetPriority(EXTI2_IRQn, 9, 0);
  HAL_NVIC_EnableIRQ(EXTI2_IRQn);

  HAL_NVIC_SetPriority(EXTI15_10_IRQn, 15, 0);
  HAL_NVIC_EnableIRQ(EXTI15_10_IRQn);

}

/* StartDefaultTask function */
void StartDefaultTask(void const * argument)
{
  /* init code for USB_DEVICE */
  MX_USB_DEVICE_Init();

  for(;;)
  {
    osDelay(1);
  }
}

void HAL_TIM_PeriodElapsedCallback(TIM_HandleTypeDef *htim)
{
  if (htim->Instance == TIM1) {
    HAL_IncTick();
  }
}

void Error_Handler(void)
{
  while(1)
  {
  }
}

/************************ (C) COPYRIGHT STMicroelectronics *****END OF FILE****/
